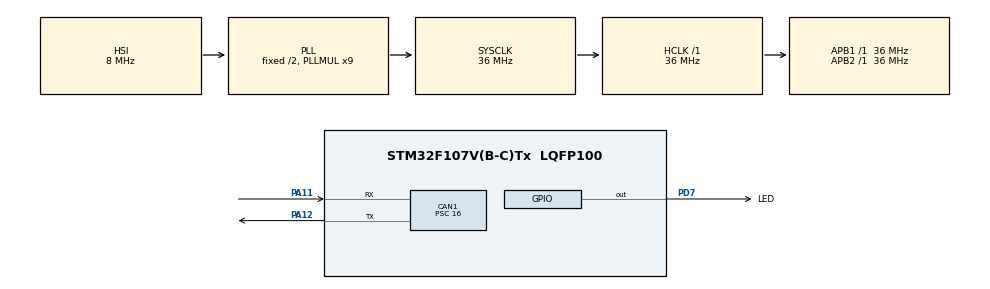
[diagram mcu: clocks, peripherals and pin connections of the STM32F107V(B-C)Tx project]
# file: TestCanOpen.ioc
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CAN1.ABOM=DISABLE
CAN1.AWUM=DISABLE
CAN1.BS1=CAN_BS1_10TQ
CAN1.BS2=CAN_BS2_7TQ
CAN1.CalculateTimeBit=8000
CAN1.CalculateTimeQuantum=444.44444444444446
CAN1.NART=DISABLE
CAN1.Prescaler=16
CAN1.RFLM=DISABLE
CAN1.TTCM=DISABLE
CAN1.TXFP=DISABLE
Mcu.Family=STM32F1
Mcu.Name=STM32F107V(B-C)Tx
Mcu.Package=LQFP100
NVIC.CAN1_RX0_IRQn=true\:0\:0\:false\:false\:true\:true
NVIC.CAN1_RX1_IRQn=true\:0\:0\:false\:false\:true\:true
NVIC.CAN1_SCE_IRQn=true\:0\:0\:false\:false\:true\:true
NVIC.CAN1_TX_IRQn=true\:0\:0\:false\:false\:true\:true
NVIC.PriorityGroup=NVIC_PRIORITYGROUP_4
PA11.Mode=Master
PA11.Signal=CAN1_RX
PA12.Mode=Master
PA12.Signal=CAN1_TX
PA13.Mode=Serial_Wire
PA13.Signal=SYS_JTMS-SWDIO
PA14.Mode=Serial_Wire
PA14.Signal=SYS_JTCK-SWCLK
PD7.GPIO_Label=LED
PD7.Signal=GPIO_Output
ProjectManager.HeapSize=0x200
ProjectManager.StackSize=0x400
ProjectManager.TargetToolchain=SW4STM32
RCC.AHBFreq_Value=36000000
RCC.APB1Freq_Value=36000000
RCC.APB1TimFreq_Value=36000000
RCC.APB2Freq_Value=36000000
RCC.APB2TimFreq_Value=36000000
RCC.HCLKFreq_Value=36000000
RCC.PLLMUL=RCC_PLL_MUL9
RCC.SYSCLKFreq_VALUE=36000000
RCC.SYSCLKSource=RCC_SYSCLKSOURCE_PLLCLK
RCC.USBFreq_Value=24000000
board=custom

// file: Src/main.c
/**
  ******************************************************************************
  * @file           : main.c
  * @brief          : Main program body
  ******************************************************************************
  ** This notice applies to any and all portions of this file
  * that are not between comment pairs USER CODE BEGIN and
  * USER CODE END. Other portions of this file, whether
  * inserted by the user or by software development tools
  * are owned by their respective copyright owners.
  *
  * COPYRIGHT(c) 2018 STMicroelectronics
  *
  * Redistribution and use in source and binary forms, with or without modification,
  * are permitted provided that the following conditions are met:
  *   1. Redistributions of source code must retain the above copyright notice,
  *      this list of conditions and the following disclaimer.
  *   2. Redistributions in binary form must reproduce the above copyright notice,
  *      this list of conditions and the following disclaimer in the documentation
  *      and/or other materials provided with the distribution.
  *   3. Neither the name of STMicroelectronics nor the names of its contributors
  *      may be used to endorse or promote products derived from this software
  *      without specific prior written permission.
  *
  * THIS SOFTWARE IS PROVIDED BY THE COPYRIGHT HOLDERS AND CONTRIBUTORS "AS IS"
  * AND ANY EXPRESS OR IMPLIED WARRANTIES, INCLUDING, BUT NOT LIMITED TO, THE
  * IMPLIED WARRANTIES OF MERCHANTABILITY AND FITNESS FOR A PARTICULAR PURPOSE ARE
  * DISCLAIMED. IN NO EVENT SHALL THE COPYRIGHT HOLDER OR CONTRIBUTORS BE LIABLE
  * FOR ANY DIRECT, INDIRECT, INCIDENTAL, SPECIAL, EXEMPLARY, OR CONSEQUENTIAL
  * DAMAGES (INCLUDING, BUT NOT LIMITED TO, PROCUREMENT OF SUBSTITUTE GOODS OR
  * SERVICES; LOSS OF USE, DATA, OR PROFITS; OR BUSINESS INTERRUPTION) HOWEVER
  * CAUSED AND ON ANY THEORY OF LIABILITY, WHETHER IN CONTRACT, STRICT LIABILITY,
  * OR TORT (INCLUDING NEGLIGENCE OR OTHERWISE) ARISING IN ANY WAY OUT OF THE USE
  * OF THIS SOFTWARE, EVEN IF ADVISED OF THE POSSIBILITY OF SUCH DAMAGE.
  *
  ******************************************************************************
  */
#include "main.h"
#include "stm32f1xx_hal.h"

CAN_HandleTypeDef hcan1;

/* USER CODE BEGIN PV */
/* Private variables ---------------------------------------------------------*/

/* USER CODE END PV */

void SystemClock_Config(void);
static void MX_GPIO_Init(void);
static void MX_CAN1_Init(void);

/* USER CODE BEGIN PFP */
/* Private function prototypes -----------------------------------------------*/

/* USER CODE END PFP */

/* USER CODE BEGIN 0 */
static CanTxMsgTypeDef        TxMessage;
static CanRxMsgTypeDef        RxMessage;
CAN_FilterConfTypeDef  sFilterConfig;
volatile uint8_t sdoRecieved = 0x00;
uint8_t sdoData[8];
void HAL_CAN_RxCpltCallback(CAN_HandleTypeDef* hcan)
{
	HAL_GPIO_TogglePin(LED_GPIO_Port,LED_Pin);

}

HAL_StatusTypeDef writeSDO32bit (uint16_t nodeId, uint32_t index, uint16_t subindex, uint16_t timeout, int32_t data)
{

		int k = -1;
	  hcan1.pTxMsg->StdId = 0x600+nodeId;
	  hcan1.pTxMsg->DLC = 0x8;
	  hcan1.pTxMsg->RTR = 0x0;
	  hcan1.pTxMsg->Data[0] = 0x23;
	  hcan1.pTxMsg->Data[1] = index&0x00FF;
	  hcan1.pTxMsg->Data[2] = (index&0xFF00)>>8;
	  hcan1.pTxMsg->Data[3] = subindex;
	  hcan1.pTxMsg->Data[4] = data&0xFF;
	  hcan1.pTxMsg->Data[5] = (data>>8) & 0xFF;
	  hcan1.pTxMsg->Data[6] = (data>>16) & 0xFF;
	  hcan1.pTxMsg->Data[7] = (data>>24) & 0xFF;
	  sdoRecieved = 0x00;
	  uint8_t err;

	  err = HAL_CAN_Transmit(&hcan1, timeout);
	  if (err!=HAL_OK)
	  {
		  return err;
	  }
	  err= HAL_CAN_Receive(&hcan1, CAN_FIFO0, timeout);
	  if (err!=HAL_OK)
	  {
		  return err;
	  }

	  if (hcan1.pRxMsg->Data[0]==0x60)
	  {
		  return HAL_OK;
	  }
	  else
	  {
		  return HAL_ERROR;
	  }

}

HAL_StatusTypeDef readSDO (uint16_t nodeId, uint32_t index, uint16_t subindex, uint16_t timeout, uint32_t *data)
{

	  hcan1.pTxMsg->StdId = 0x600+nodeId;
	  hcan1.pTxMsg->DLC = 0x8;
	  hcan1.pTxMsg->RTR = 0x0;
	  hcan1.pTxMsg->Data[0] = 0x40;
	  hcan1.pTxMsg->Data[1] = index&0x00FF;
	  hcan1.pTxMsg->Data[2] = (index&0xFF00)>>8;
	  hcan1.pTxMsg->Data[3] = subindex;
	  hcan1.pTxMsg->Data[4] = 0x00;
	  hcan1.pTxMsg->Data[5] = 0x00;
	  hcan1.pTxMsg->Data[6] = 0x00;
	  hcan1.pTxMsg->Data[7] = 0x00;
	  sdoRecieved = 0x00;
	  uint8_t err;

	  err = HAL_CAN_Transmit(&hcan1, timeout);
	  if (err!=HAL_OK)
	  {
		  return err;
	  }
	  err= HAL_CAN_Receive(&hcan1, CAN_FIFO0, timeout);
	  if (err!=HAL_OK)
	  {
		  return err;
	  }

	  if (hcan1.pRxMsg->Data[0]==0x43)
	  {
		  *data =hcan1.pRxMsg->Data[4]<<0 |
				 hcan1.pRxMsg->Data[5]<<8 |
				 hcan1.pRxMsg->Data[6]<<16 |
				 hcan1.pRxMsg->Data[7]<<24 ;
		  return HAL_OK;
	  }
	  else
	  {
		  return HAL_ERROR;
	  }

}
/* USER CODE END 0 */

int main(void)
{

  /* MCU Configuration----------------------------------------------------------*/

  /* Reset of all peripherals, Initializes the Flash interface and the Systick. */
  HAL_Init();

  /* Configure the system clock */
  SystemClock_Config();

  /* Initialize all configured peripherals */
  MX_GPIO_Init();
  MX_CAN1_Init();
  /* USER CODE BEGIN 2 */
  sFilterConfig.FilterNumber = 0;
	sFilterConfig.FilterMode = CAN_FILTERMODE_IDMASK;
	sFilterConfig.FilterScale = CAN_FILTERSCALE_32BIT;
	sFilterConfig.FilterIdHigh = 0x0000;
	sFilterConfig.FilterIdLow = 0x0000;
	sFilterConfig.FilterMaskIdHigh = 0x0000;
	sFilterConfig.FilterMaskIdLow = 0x0000;
	sFilterConfig.FilterFIFOAssignment = 0;
	sFilterConfig.FilterActivation = ENABLE;
	sFilterConfig.BankNumber = 1;

	if (HAL_CAN_ConfigFilter(&hcan1, &sFilterConfig) != HAL_OK)
	{
	/* Filter configuration Error */
	Error_Handler();
	}
  /* USER CODE END 2 */

  /* Infinite loop */
  /* USER CODE BEGIN WHILE */

  hcan1.pTxMsg = &TxMessage;
  hcan1.pRxMsg = &RxMessage;

  while (1)
  {

  /* USER CODE END WHILE */

  /* USER CODE BEGIN 3 */

	  uint32_t data = 0;
	  writeSDO32bit(127,0x3300, 0x00,5, 1000);
	  HAL_Delay(10);
	  writeSDO32bit(127,0x3300, 0x00,5, -1000);
	  HAL_Delay(10);

	  volatile uint8_t err = readSDO(127,0x3110, 0x00,5, &data);

	  //HAL_Delay(300);

  }
  /* USER CODE END 3 */

}

void SystemClock_Config(void)
{

  RCC_OscInitTypeDef RCC_OscInitStruct;
  RCC_ClkInitTypeDef RCC_ClkInitStruct;

    /**Initializes the CPU, AHB and APB busses clocks
    */
  RCC_OscInitStruct.OscillatorType = RCC_OSCILLATORTYPE_HSI;
  RCC_OscInitStruct.HSIState = RCC_HSI_ON;
  RCC_OscInitStruct.HSICalibrationValue = 16;
  RCC_OscInitStruct.Prediv1Source = RCC_PREDIV1_SOURCE_HSE;
  RCC_OscInitStruct.PLL.PLLState = RCC_PLL_ON;
  RCC_OscInitStruct.PLL.PLLSource = RCC_PLLSOURCE_HSI_DIV2;
  RCC_OscInitStruct.PLL.PLLMUL = RCC_PLL_MUL9;
  RCC_OscInitStruct.PLL2.PLL2State = RCC_PLL_NONE;
  if (HAL_RCC_OscConfig(&RCC_OscInitStruct) != HAL_OK)
  {
    _Error_Handler(__FILE__, __LINE__);
  }

    /**Initializes the CPU, AHB and APB busses clocks
    */
  RCC_ClkInitStruct.ClockType = RCC_CLOCKTYPE_HCLK|RCC_CLOCKTYPE_SYSCLK
                              |RCC_CLOCKTYPE_PCLK1|RCC_CLOCKTYPE_PCLK2;
  RCC_ClkInitStruct.SYSCLKSource = RCC_SYSCLKSOURCE_PLLCLK;
  RCC_ClkInitStruct.AHBCLKDivider = RCC_SYSCLK_DIV1;
  RCC_ClkInitStruct.APB1CLKDivider = RCC_HCLK_DIV1;
  RCC_ClkInitStruct.APB2CLKDivider = RCC_HCLK_DIV1;

  if (HAL_RCC_ClockConfig(&RCC_ClkInitStruct, FLASH_LATENCY_1) != HAL_OK)
  {
    _Error_Handler(__FILE__, __LINE__);
  }

    /**Configure the Systick interrupt time
    */
  HAL_SYSTICK_Config(HAL_RCC_GetHCLKFreq()/1000);

    /**Configure the Systick
    */
  HAL_SYSTICK_CLKSourceConfig(SYSTICK_CLKSOURCE_HCLK);

    /**Configure the Systick interrupt time
    */
  __HAL_RCC_PLLI2S_ENABLE();

  /* SysTick_IRQn interrupt configuration */
  HAL_NVIC_SetPriority(SysTick_IRQn, 0, 0);
}

/* CAN1 init function */
static void MX_CAN1_Init(void)
{

  hcan1.Instance = CAN1;
  hcan1.Init.Prescaler = 16;
  hcan1.Init.Mode = CAN_MODE_NORMAL;
  hcan1.Init.SJW = CAN_SJW_1TQ;
  hcan1.Init.BS1 = CAN_BS1_10TQ;
  hcan1.Init.BS2 = CAN_BS2_7TQ;
  hcan1.Init.TTCM = DISABLE;
  hcan1.Init.ABOM = DISABLE;
  hcan1.Init.AWUM = DISABLE;
  hcan1.Init.NART = DISABLE;
  hcan1.Init.RFLM = DISABLE;
  hcan1.Init.TXFP = DISABLE;
  if (HAL_CAN_Init(&hcan1) != HAL_OK)
  {
    _Error_Handler(__FILE__, __LINE__);
  }

}

/** Configure pins as
        * Analog
        * Input
        * Output
        * EVENT_OUT
        * EXTI
*/
static void MX_GPIO_Init(void)
{

  GPIO_InitTypeDef GPIO_InitStruct;

  /* GPIO Ports Clock Enable */
  __HAL_RCC_GPIOA_CLK_ENABLE();
  __HAL_RCC_GPIOD_CLK_ENABLE();

  /*Configure GPIO pin Output Level */
  HAL_GPIO_WritePin(LED_GPIO_Port, LED_Pin, GPIO_PIN_RESET);

  /*Configure GPIO pin : LED_Pin */
  GPIO_InitStruct.Pin = LED_Pin;
  GPIO_InitStruct.Mode = GPIO_MODE_OUTPUT_PP;
  GPIO_InitStruct.Pull = GPIO_NOPULL;
  GPIO_InitStruct.Speed = GPIO_SPEED_FREQ_LOW;
  HAL_GPIO_Init(LED_GPIO_Port, &GPIO_InitStruct);

}

void _Error_Handler(char *file, int line)
{
  while(1)
  {
  }
}

/************************ (C) COPYRIGHT STMicroelectronics *****END OF FILE****/
